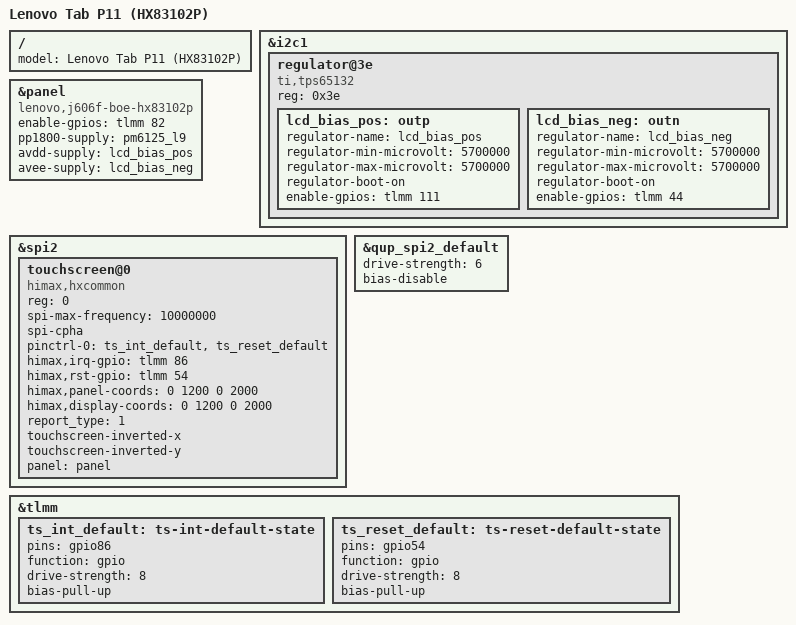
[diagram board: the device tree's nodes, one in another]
// SPDX-License-Identifier: (GPL-2.0+ OR BSD-3-Clause)
/*
 * Lenovo Tab P11 (TB-J606F), SKU with the BOE panel driven by a Himax HX83102P
 * TDDI (stock cmdline: msm_drm.dsi_display0=qcom,mdss_dsi_himax83102p_boe_2k_video).
 * The base dts describes the NT36523W SKU; this file swaps the panel and adds
 * the Himax touch. Values from the stock DT (see notes/stock_dt/).
 */

#include "sm6115p-lenovo-j606f.dts"
#include "sm6115p-lenovo-j606f-common.dtsi"

/ {
	model = "Lenovo Tab P11 (HX83102P)";
};

&i2c1 {
	regulator@3e {
		compatible = "ti,tps65132";
		reg = <0x3e>;

		lcd_bias_pos: outp {
			regulator-name = "lcd_bias_pos";
			/* stock: VPOS/VNEG = 0x11 */
			regulator-min-microvolt = <5700000>;
			regulator-max-microvolt = <5700000>;
			regulator-boot-on;
			enable-gpios = <&tlmm 111 GPIO_ACTIVE_HIGH>;
		};

		lcd_bias_neg: outn {
			regulator-name = "lcd_bias_neg";
			/* stock: VPOS/VNEG = 0x11 */
			regulator-min-microvolt = <5700000>;
			regulator-max-microvolt = <5700000>;
			regulator-boot-on;
			enable-gpios = <&tlmm 44 GPIO_ACTIVE_HIGH>;
		};
	};
};

&panel {
	compatible = "lenovo,j606f-boe-hx83102p", "himax,hx83102";
	/delete-property/ reset-gpios;
	/delete-property/ vddio-supply;

	enable-gpios = <&tlmm 82 GPIO_ACTIVE_HIGH>;
	pp1800-supply = <&pm6125_l9>;
	avdd-supply = <&lcd_bias_pos>;
	avee-supply = <&lcd_bias_neg>;
};

/*
 * Himax HX83102E touch (TDDI with the HX83102P panel), zero-flash: the firmware
 * (Himax_firmware.bin) is loaded by the host after every panel power-up.
 * Values from the stock himax_ts@0 node.
 */
&spi2 {
	status = "okay";

	touchscreen@0 {
		compatible = "himax,hxcommon";
		reg = <0>;
		spi-max-frequency = <10000000>;
		spi-cpha;
		pinctrl-0 = <&ts_int_default>, <&ts_reset_default>;
		pinctrl-names = "default";

		himax,irq-gpio = <&tlmm 86 GPIO_ACTIVE_HIGH>;
		himax,rst-gpio = <&tlmm 54 GPIO_ACTIVE_HIGH>;
		himax,panel-coords = <0 1200 0 2000>;
		himax,display-coords = <0 1200 0 2000>;
		report_type = <1>;
		/* the panel is mounted upside down (rotation = <180>), touch reports chassis coordinates */
		touchscreen-inverted-x;
		touchscreen-inverted-y;
		panel = <&panel>;
	};
};

&qup_spi2_default {
	/* stock qupv3_se2_spi_active / cs0_active */
	drive-strength = <6>;
	bias-disable;
	/delete-property/ bias-pull-up;
};

&tlmm {
	ts_int_default: ts-int-default-state {
		pins = "gpio86";
		function = "gpio";
		drive-strength = <8>;
		bias-pull-up;
	};

	ts_reset_default: ts-reset-default-state {
		pins = "gpio54";
		function = "gpio";
		drive-strength = <8>;
		bias-pull-up;
	};
};
